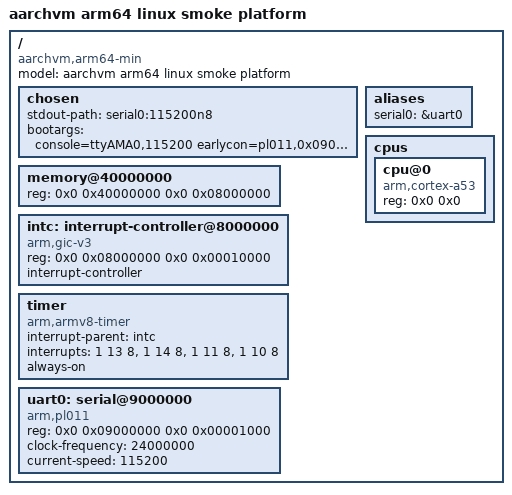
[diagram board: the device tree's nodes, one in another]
/dts-v1/;

/ {
	model = "aarchvm arm64 linux smoke platform";
	compatible = "aarchvm,arm64-min";
	#address-cells = <2>;
	#size-cells = <2>;

	chosen {
		stdout-path = "serial0:115200n8";
		bootargs = "console=ttyAMA0,115200 earlycon=pl011,0x09000000 ignore_loglevel";
	};

	aliases {
		serial0 = &uart0;
	};

	cpus {
		#address-cells = <2>;
		#size-cells = <0>;

		cpu@0 {
			device_type = "cpu";
			compatible = "arm,cortex-a53";
			reg = <0x0 0x0>;
		};
	};

	memory@40000000 {
		device_type = "memory";
		reg = <0x0 0x40000000 0x0 0x08000000>;
	};

	intc: interrupt-controller@8000000 {
		compatible = "arm,gic-v3";
		reg = <0x0 0x08000000 0x0 0x00010000>;
		interrupt-controller;
		#interrupt-cells = <3>;
		#address-cells = <2>;
		#size-cells = <2>;
		ranges;
	};

	timer {
		compatible = "arm,armv8-timer";
		interrupt-parent = <&intc>;
		interrupts = <1 13 8>, <1 14 8>, <1 11 8>, <1 10 8>;
		always-on;
	};

	uart0: serial@9000000 {
		compatible = "arm,pl011", "arm,primecell";
		reg = <0x0 0x09000000 0x0 0x00001000>;
		clock-frequency = <24000000>;
		current-speed = <115200>;
		status = "okay";
	};
};
